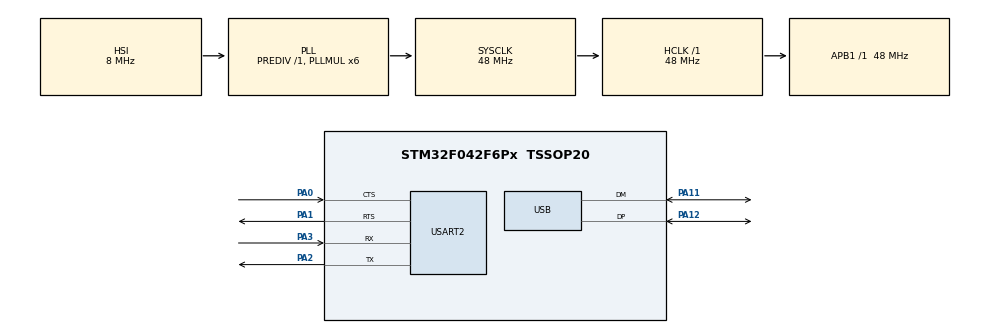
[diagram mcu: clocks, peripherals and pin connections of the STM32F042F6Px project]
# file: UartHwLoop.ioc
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Mcu.Family=STM32F0
Mcu.Name=STM32F042F6Px
Mcu.Package=TSSOP20
NVIC.USART2_IRQn=true\:0\:0\:false\:false\:true\:true\:true\:true
NVIC.USB_IRQn=true\:0\:0\:false\:false\:true\:false\:true\:true
PA0.Mode=CTS_RTS
PA0.Signal=USART2_CTS
PA1.Mode=CTS_RTS
PA1.Signal=USART2_RTS
PA11.Mode=Device
PA11.Signal=USB_DM
PA12.Mode=Device
PA12.Signal=USB_DP
PA13.Mode=Serial_Wire
PA13.Signal=SYS_SWDIO
PA14.Mode=Serial_Wire
PA14.Signal=SYS_SWCLK
PA2.Mode=Asynchronous
PA2.Signal=USART2_TX
PA3.Mode=Asynchronous
PA3.Signal=USART2_RX
ProjectManager.HeapSize=0x200
ProjectManager.StackSize=0x400
ProjectManager.TargetToolchain=STM32CubeIDE
RCC.AHBFreq_Value=48000000
RCC.APB1Freq_Value=48000000
RCC.APB1TimFreq_Value=48000000
RCC.HCLKFreq_Value=48000000
RCC.PLLMUL=RCC_PLL_MUL6
RCC.SYSCLKFreq_VALUE=48000000
RCC.SYSCLKSource=RCC_SYSCLKSOURCE_PLLCLK
RCC.USBFreq_Value=48000000
USART2.VirtualMode-Asynchronous=VM_ASYNC
USB_DEVICE.APP_RX_DATA_SIZE=64
USB_DEVICE.APP_TX_DATA_SIZE=64
USB_DEVICE.CLASS_NAME_FS=CDC
USB_DEVICE.PID_CDC_FS=0x5740
USB_DEVICE.PRODUCT_STRING_CDC_FS=USB F042 VCP
USB_DEVICE.VID=0x8c4
USB_DEVICE.VirtualMode=Cdc
USB_DEVICE.VirtualModeFS=Cdc_FS
VP_SYS_VS_PINREMAP.Mode=PINREMAP
VP_USB_DEVICE_VS_USB_DEVICE_CDC_FS.Mode=CDC_FS
board=custom

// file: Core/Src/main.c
/* USER CODE BEGIN Header */
/**
  ******************************************************************************
  * @file           : main.c
  * @brief          : Main program body
  ******************************************************************************
  * @attention
  *
  * Copyright (c) 2024 STMicroelectronics.
  * All rights reserved.
  *
  * This software is licensed under terms that can be found in the LICENSE file
  * in the root directory of this software component.
  * If no LICENSE file comes with this software, it is provided AS-IS.
  *
  ******************************************************************************
  */
/* USER CODE END Header */
#include "main.h"
#include "usb_device.h"

UART_HandleTypeDef huart2;

void SystemClock_Config(void);
static void MX_GPIO_Init(void);
static void MX_USART2_UART_Init(void);

/* USER CODE BEGIN 0 */
extern void runApp();
/* USER CODE END 0 */

int main(void)
{

  /* MCU Configuration--------------------------------------------------------*/

  /* Reset of all peripherals, Initializes the Flash interface and the Systick. */
  HAL_Init();

  /* Configure the system clock */
  SystemClock_Config();

  /* Initialize all configured peripherals */
  MX_GPIO_Init();
  MX_USART2_UART_Init();
  MX_USB_DEVICE_Init();
  /* USER CODE BEGIN 2 */
  runApp();
  /* USER CODE END 2 */

  /* Infinite loop */
  while (1)
  {

  }
}

void SystemClock_Config(void)
{
  RCC_OscInitTypeDef RCC_OscInitStruct = {0};
  RCC_ClkInitTypeDef RCC_ClkInitStruct = {0};
  RCC_PeriphCLKInitTypeDef PeriphClkInit = {0};

  /** Initializes the RCC Oscillators according to the specified parameters
  * in the RCC_OscInitTypeDef structure.
  */
  RCC_OscInitStruct.OscillatorType = RCC_OSCILLATORTYPE_HSI|RCC_OSCILLATORTYPE_HSI48;
  RCC_OscInitStruct.HSIState = RCC_HSI_ON;
  RCC_OscInitStruct.HSI48State = RCC_HSI48_ON;
  RCC_OscInitStruct.HSICalibrationValue = RCC_HSICALIBRATION_DEFAULT;
  RCC_OscInitStruct.PLL.PLLState = RCC_PLL_ON;
  RCC_OscInitStruct.PLL.PLLSource = RCC_PLLSOURCE_HSI;
  RCC_OscInitStruct.PLL.PLLMUL = RCC_PLL_MUL6;
  RCC_OscInitStruct.PLL.PREDIV = RCC_PREDIV_DIV1;
  if (HAL_RCC_OscConfig(&RCC_OscInitStruct) != HAL_OK)
  {
    Error_Handler();
  }

  /** Initializes the CPU, AHB and APB buses clocks
  */
  RCC_ClkInitStruct.ClockType = RCC_CLOCKTYPE_HCLK|RCC_CLOCKTYPE_SYSCLK
                              |RCC_CLOCKTYPE_PCLK1;
  RCC_ClkInitStruct.SYSCLKSource = RCC_SYSCLKSOURCE_PLLCLK;
  RCC_ClkInitStruct.AHBCLKDivider = RCC_SYSCLK_DIV1;
  RCC_ClkInitStruct.APB1CLKDivider = RCC_HCLK_DIV1;

  if (HAL_RCC_ClockConfig(&RCC_ClkInitStruct, FLASH_LATENCY_1) != HAL_OK)
  {
    Error_Handler();
  }
  PeriphClkInit.PeriphClockSelection = RCC_PERIPHCLK_USB;
  PeriphClkInit.UsbClockSelection = RCC_USBCLKSOURCE_HSI48;

  if (HAL_RCCEx_PeriphCLKConfig(&PeriphClkInit) != HAL_OK)
  {
    Error_Handler();
  }
}

static void MX_USART2_UART_Init(void)
{

  huart2.Instance = USART2;
  huart2.Init.BaudRate = 38400;
  huart2.Init.WordLength = UART_WORDLENGTH_8B;
  huart2.Init.StopBits = UART_STOPBITS_1;
  huart2.Init.Parity = UART_PARITY_NONE;
  huart2.Init.Mode = UART_MODE_TX_RX;
  huart2.Init.HwFlowCtl = UART_HWCONTROL_RTS_CTS;
  huart2.Init.OverSampling = UART_OVERSAMPLING_16;
  huart2.Init.OneBitSampling = UART_ONE_BIT_SAMPLE_DISABLE;
  huart2.AdvancedInit.AdvFeatureInit = UART_ADVFEATURE_NO_INIT;
  if (HAL_UART_Init(&huart2) != HAL_OK)
  {
    Error_Handler();
  }

}

static void MX_GPIO_Init(void)
{

  /* GPIO Ports Clock Enable */
  __HAL_RCC_GPIOA_CLK_ENABLE();

}

void Error_Handler(void)
{
  __disable_irq();
  while (1)
  {
  }
}
